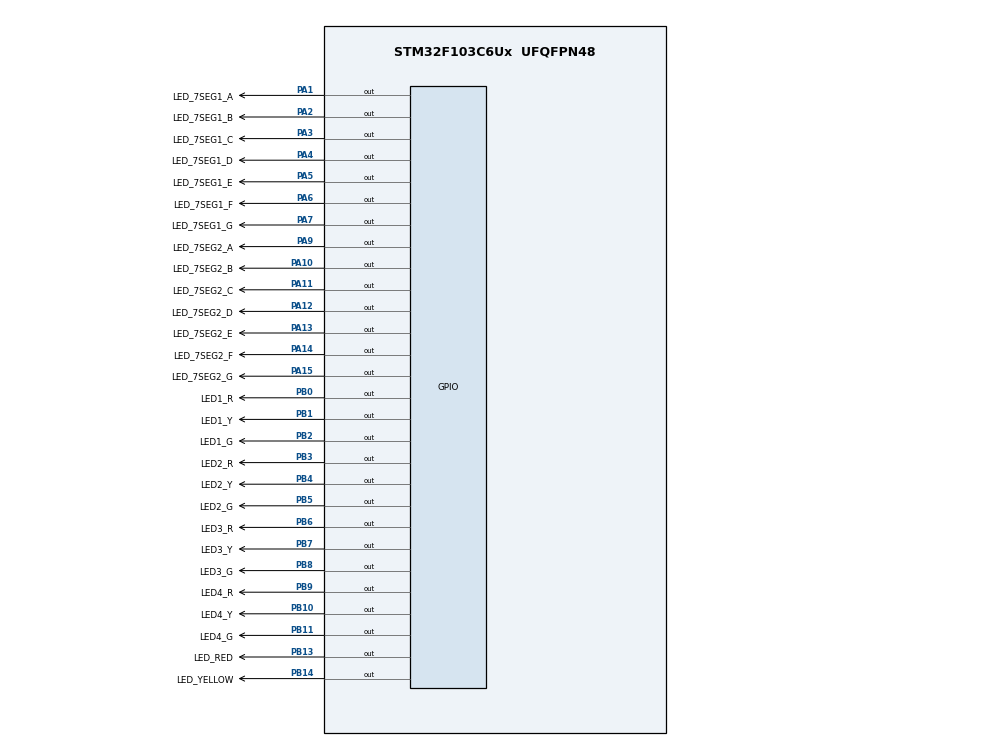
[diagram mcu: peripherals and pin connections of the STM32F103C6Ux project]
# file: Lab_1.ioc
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Mcu.Family=STM32F1
Mcu.Name=STM32F103C6Ux
Mcu.Package=UFQFPN48
NVIC.PriorityGroup=NVIC_PRIORITYGROUP_4
PA1.GPIO_Label=LED_7SEG1_A
PA1.Signal=GPIO_Output
PA10.GPIO_Label=LED_7SEG2_B
PA10.Signal=GPIO_Output
PA11.GPIO_Label=LED_7SEG2_C
PA11.Signal=GPIO_Output
PA12.GPIO_Label=LED_7SEG2_D
PA12.Signal=GPIO_Output
PA13.GPIO_Label=LED_7SEG2_E
PA13.Signal=GPIO_Output
PA14.GPIO_Label=LED_7SEG2_F
PA14.Signal=GPIO_Output
PA15.GPIO_Label=LED_7SEG2_G
PA15.Signal=GPIO_Output
PA2.GPIO_Label=LED_7SEG1_B
PA2.Signal=GPIO_Output
PA3.GPIO_Label=LED_7SEG1_C
PA3.Signal=GPIO_Output
PA4.GPIO_Label=LED_7SEG1_D
PA4.Signal=GPIO_Output
PA5.GPIO_Label=LED_7SEG1_E
PA5.Signal=GPIO_Output
PA6.GPIO_Label=LED_7SEG1_F
PA6.Signal=GPIO_Output
PA7.GPIO_Label=LED_7SEG1_G
PA7.Signal=GPIO_Output
PA9.GPIO_Label=LED_7SEG2_A
PA9.Signal=GPIO_Output
PB0.GPIO_Label=LED1_R
PB0.Signal=GPIO_Output
PB1.GPIO_Label=LED1_Y
PB1.Signal=GPIO_Output
PB10.GPIO_Label=LED4_Y
PB10.Signal=GPIO_Output
PB11.GPIO_Label=LED4_G
PB11.Signal=GPIO_Output
PB13.GPIO_Label=LED_RED
PB13.Signal=GPIO_Output
PB14.GPIO_Label=LED_YELLOW
PB14.Signal=GPIO_Output
PB2.GPIO_Label=LED1_G
PB2.Signal=GPIO_Output
PB3.GPIO_Label=LED2_R
PB3.Signal=GPIO_Output
PB4.GPIO_Label=LED2_Y
PB4.Signal=GPIO_Output
PB5.GPIO_Label=LED2_G
PB5.Signal=GPIO_Output
PB6.GPIO_Label=LED3_R
PB6.Signal=GPIO_Output
PB7.GPIO_Label=LED3_Y
PB7.Signal=GPIO_Output
PB8.GPIO_Label=LED3_G
PB8.Signal=GPIO_Output
PB9.GPIO_Label=LED4_R
PB9.Signal=GPIO_Output
ProjectManager.HeapSize=0x200
ProjectManager.StackSize=0x400
ProjectManager.TargetToolchain=STM32CubeIDE
RCC.APB1Freq_Value=8000000
RCC.APB2Freq_Value=8000000
VP_SYS_VS_ND.Mode=No_Debug
board=custom

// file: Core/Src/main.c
/* USER CODE BEGIN Header */
/**
  ******************************************************************************
  * @file           : main.c
  * @brief          : Main program body
  ******************************************************************************
  * @attention
  *
  * <h2><center>&copy; Copyright (c) 2024 STMicroelectronics.
  * All rights reserved.</center></h2>
  *
  * This software component is licensed by ST under BSD 3-Clause license,
  * the "License"; You may not use this file except in compliance with the
  * License. You may obtain a copy of the License at:
  *                        opensource.org/licenses/BSD-3-Clause
  *
  ******************************************************************************
  */
/* USER CODE END Header */
#include "main.h"

/* USER CODE BEGIN Includes */
#include "global.h"
#include "ex1.h"
#include "ex2.h"
#include "ex3.h"
#include "ex4.h"
#include "ex5.h"
#include "ex6-to-ex10.h"
/* USER CODE END Includes */

void SystemClock_Config(void);
static void MX_GPIO_Init(void);

int main(void)
{

  /* MCU Configuration--------------------------------------------------------*/

  /* Reset of all peripherals, Initializes the Flash interface and the Systick. */
  HAL_Init();

  /* Configure the system clock */
  SystemClock_Config();

  /* Initialize all configured peripherals */
  MX_GPIO_Init();
  /* USER CODE BEGIN 2 */
//  init_ex1();
//  init_ex2();
//  init_ex3();
//  init_ex4();
//  init_ex5();
  init_ex6_to_ex10();
  /* USER CODE END 2 */

  /* Infinite loop */
  /* USER CODE BEGIN WHILE */
  while (1)
  {
//	ex1_run();
//	ex2_run();
//	ex3_run();
//	ex4_run();
//	ex5_run();
//	ex6_run();
//	clearAllClock();
//	setNumberOnClock(led_counter);
//	clearNumberOnClock(led_counter);
	ex10_run();
	HAL_Delay(1000);
    /* USER CODE END WHILE */

  }
}

void SystemClock_Config(void)
{
  RCC_OscInitTypeDef RCC_OscInitStruct = {0};
  RCC_ClkInitTypeDef RCC_ClkInitStruct = {0};

  /** Initializes the RCC Oscillators according to the specified parameters
  * in the RCC_OscInitTypeDef structure.
  */
  RCC_OscInitStruct.OscillatorType = RCC_OSCILLATORTYPE_HSI;
  RCC_OscInitStruct.HSIState = RCC_HSI_ON;
  RCC_OscInitStruct.HSICalibrationValue = RCC_HSICALIBRATION_DEFAULT;
  RCC_OscInitStruct.PLL.PLLState = RCC_PLL_NONE;
  if (HAL_RCC_OscConfig(&RCC_OscInitStruct) != HAL_OK)
  {
    Error_Handler();
  }
  /** Initializes the CPU, AHB and APB buses clocks
  */
  RCC_ClkInitStruct.ClockType = RCC_CLOCKTYPE_HCLK|RCC_CLOCKTYPE_SYSCLK
                              |RCC_CLOCKTYPE_PCLK1|RCC_CLOCKTYPE_PCLK2;
  RCC_ClkInitStruct.SYSCLKSource = RCC_SYSCLKSOURCE_HSI;
  RCC_ClkInitStruct.AHBCLKDivider = RCC_SYSCLK_DIV1;
  RCC_ClkInitStruct.APB1CLKDivider = RCC_HCLK_DIV1;
  RCC_ClkInitStruct.APB2CLKDivider = RCC_HCLK_DIV1;

  if (HAL_RCC_ClockConfig(&RCC_ClkInitStruct, FLASH_LATENCY_0) != HAL_OK)
  {
    Error_Handler();
  }
}

static void MX_GPIO_Init(void)
{
  GPIO_InitTypeDef GPIO_InitStruct = {0};

  /* GPIO Ports Clock Enable */
  __HAL_RCC_GPIOA_CLK_ENABLE();
  __HAL_RCC_GPIOB_CLK_ENABLE();

  /*Configure GPIO pin Output Level */
  HAL_GPIO_WritePin(GPIOA, LED_7SEG1_A_Pin|LED_7SEG1_B_Pin|LED_7SEG1_C_Pin|LED_7SEG1_D_Pin
                          |LED_7SEG1_E_Pin|LED_7SEG1_F_Pin|LED_7SEG1_G_Pin|LED_7SEG2_A_Pin
                          |LED_7SEG2_B_Pin|LED_7SEG2_C_Pin|LED_7SEG2_D_Pin|LED_7SEG2_E_Pin
                          |LED_7SEG2_F_Pin|LED_7SEG2_G_Pin, GPIO_PIN_RESET);

  /*Configure GPIO pin Output Level */
  HAL_GPIO_WritePin(GPIOB, LED1_R_Pin|LED1_Y_Pin|LED1_G_Pin|LED4_Y_Pin
                          |LED4_G_Pin|LED_RED_Pin|LED_YELLOW_Pin|LED2_R_Pin
                          |LED2_Y_Pin|LED2_G_Pin|LED3_R_Pin|LED3_Y_Pin
                          |LED3_G_Pin|LED4_R_Pin, GPIO_PIN_RESET);

  /*Configure GPIO pins : LED_7SEG1_A_Pin LED_7SEG1_B_Pin LED_7SEG1_C_Pin LED_7SEG1_D_Pin
                           LED_7SEG1_E_Pin LED_7SEG1_F_Pin LED_7SEG1_G_Pin LED_7SEG2_A_Pin
                           LED_7SEG2_B_Pin LED_7SEG2_C_Pin LED_7SEG2_D_Pin LED_7SEG2_E_Pin
                           LED_7SEG2_F_Pin LED_7SEG2_G_Pin */
  GPIO_InitStruct.Pin = LED_7SEG1_A_Pin|LED_7SEG1_B_Pin|LED_7SEG1_C_Pin|LED_7SEG1_D_Pin
                          |LED_7SEG1_E_Pin|LED_7SEG1_F_Pin|LED_7SEG1_G_Pin|LED_7SEG2_A_Pin
                          |LED_7SEG2_B_Pin|LED_7SEG2_C_Pin|LED_7SEG2_D_Pin|LED_7SEG2_E_Pin
                          |LED_7SEG2_F_Pin|LED_7SEG2_G_Pin;
  GPIO_InitStruct.Mode = GPIO_MODE_OUTPUT_PP;
  GPIO_InitStruct.Pull = GPIO_NOPULL;
  GPIO_InitStruct.Speed = GPIO_SPEED_FREQ_LOW;
  HAL_GPIO_Init(GPIOA, &GPIO_InitStruct);

  /*Configure GPIO pins : LED1_R_Pin LED1_Y_Pin LED1_G_Pin LED4_Y_Pin
                           LED4_G_Pin LED_RED_Pin LED_YELLOW_Pin LED2_R_Pin
                           LED2_Y_Pin LED2_G_Pin LED3_R_Pin LED3_Y_Pin
                           LED3_G_Pin LED4_R_Pin */
  GPIO_InitStruct.Pin = LED1_R_Pin|LED1_Y_Pin|LED1_G_Pin|LED4_Y_Pin
                          |LED4_G_Pin|LED_RED_Pin|LED_YELLOW_Pin|LED2_R_Pin
                          |LED2_Y_Pin|LED2_G_Pin|LED3_R_Pin|LED3_Y_Pin
                          |LED3_G_Pin|LED4_R_Pin;
  GPIO_InitStruct.Mode = GPIO_MODE_OUTPUT_PP;
  GPIO_InitStruct.Pull = GPIO_NOPULL;
  GPIO_InitStruct.Speed = GPIO_SPEED_FREQ_LOW;
  HAL_GPIO_Init(GPIOB, &GPIO_InitStruct);

}

void Error_Handler(void)
{
  __disable_irq();
  while (1)
  {
  }
}

/************************ (C) COPYRIGHT STMicroelectronics *****END OF FILE****/
